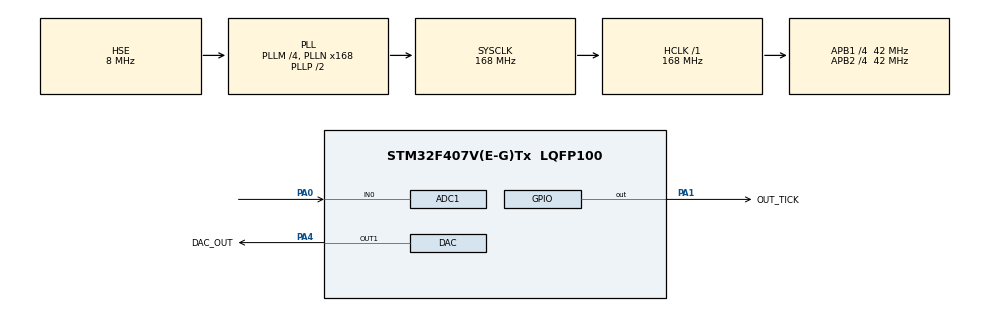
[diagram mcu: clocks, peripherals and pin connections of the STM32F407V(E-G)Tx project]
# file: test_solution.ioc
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ADC1.Channel-19\#ChannelRegularConversion=ADC_CHANNEL_0
ADC1.ClockPrescaler=ADC_CLOCK_SYNC_PCLK_DIV4
ADC1.ContinuousConvMode=DISABLE
ADC1.DMAContinuousRequests=ENABLE
ADC1.ExternalTrigConv=ADC_EXTERNALTRIGCONV_T2_TRGO
ADC1.NbrOfConversionFlag=1
ADC1.Rank-19\#ChannelRegularConversion=1
ADC1.SamplingTime-19\#ChannelRegularConversion=ADC_SAMPLETIME_3CYCLES
ADC1.ScanConvMode=DISABLE
ADC1.master=1
DAC.DAC_OutputBuffer=DAC_OUTPUTBUFFER_ENABLE
Dma.ADC1.0.Direction=DMA_PERIPH_TO_MEMORY
Dma.ADC1.0.FIFOMode=DMA_FIFOMODE_DISABLE
Dma.ADC1.0.Instance=DMA2_Stream0
Dma.ADC1.0.MemDataAlignment=DMA_MDATAALIGN_HALFWORD
Dma.ADC1.0.MemInc=DMA_MINC_ENABLE
Dma.ADC1.0.Mode=DMA_CIRCULAR
Dma.ADC1.0.PeriphDataAlignment=DMA_PDATAALIGN_HALFWORD
Dma.ADC1.0.PeriphInc=DMA_PINC_DISABLE
Dma.ADC1.0.Priority=DMA_PRIORITY_LOW
Dma.Request0=ADC1
Mcu.Family=STM32F4
Mcu.Name=STM32F407V(E-G)Tx
Mcu.Package=LQFP100
NVIC.DMA2_Stream0_IRQn=true\:0\:0\:false\:false\:true\:false\:true
NVIC.PriorityGroup=NVIC_PRIORITYGROUP_0
PA0-WKUP.Signal=ADCx_IN0
PA1.GPIO_Label=OUT_TICK
PA1.GPIO_PuPd=GPIO_PULLUP
PA1.Signal=GPIO_Output
PA4.GPIO_Label=DAC_OUT
PA4.Signal=COMP_DAC1_group
PC14-OSC32_IN.Mode=LSE-External-Oscillator
PC14-OSC32_IN.Signal=RCC_OSC32_IN
PC15-OSC32_OUT.Mode=LSE-External-Oscillator
PC15-OSC32_OUT.Signal=RCC_OSC32_OUT
PH0-OSC_IN.Mode=HSE-External-Oscillator
PH0-OSC_IN.Signal=RCC_OSC_IN
PH1-OSC_OUT.Mode=HSE-External-Oscillator
PH1-OSC_OUT.Signal=RCC_OSC_OUT
ProjectManager.HeapSize=0x200
ProjectManager.StackSize=0x400
ProjectManager.TargetToolchain=MDK-ARM V5.27
RCC.48MHZClocksFreq_Value=84000000
RCC.AHBFreq_Value=168000000
RCC.APB1CLKDivider=RCC_HCLK_DIV4
RCC.APB1Freq_Value=42000000
RCC.APB1TimFreq_Value=84000000
RCC.APB2CLKDivider=RCC_HCLK_DIV4
RCC.APB2Freq_Value=42000000
RCC.APB2TimFreq_Value=84000000
RCC.CortexFreq_Value=168000000
RCC.HCLKFreq_Value=168000000
RCC.HSE_VALUE=8000000
RCC.HSI_VALUE=16000000
RCC.PLLM=4
RCC.PLLN=168
RCC.PLLSourceVirtual=RCC_PLLSOURCE_HSE
RCC.SYSCLKFreq_VALUE=168000000
RCC.SYSCLKSource=RCC_SYSCLKSOURCE_PLLCLK
RCC.VCOOutputFreq_Value=336000000
SH.ADCx_IN0.0=ADC1_IN0,IN0
SH.COMP_DAC1_group.0=DAC_OUT1,DAC_OUT1
TIM2.AutoReloadPreload=TIM_AUTORELOAD_PRELOAD_ENABLE
TIM2.ClockDivision=TIM_CLOCKDIVISION_DIV1
TIM2.Period=200
TIM2.Prescaler=83
TIM2.TIM_MasterOutputTrigger=TIM_TRGO_UPDATE
VP_RTC_VS_RTC_Activate.Mode=RTC_Enabled
VP_TIM2_VS_ClockSourceINT.Mode=Internal
board=custom

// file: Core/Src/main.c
/* USER CODE BEGIN Header */
/**
  ******************************************************************************
  * @file           : main.c
  * @brief          : Тестовое задание
	* @authors        : Селютин Алексей
	* @date           : 19.11.2023
	* @todo           Что можно добавить: - калибровку ADC и измерение Vref. Это может повысить точность измерений.
	* @n Можно ввести два буфера для DMA и включить мультибуфер (актуально для высокой частоты дискредитации ADC)
	* @warning По причине отсутствия выхода SWO ST-LINK2 - вывод отладочной информации в терминал не тестировался.
	* @n Для включения вывода в терминал должно быть достаточно включить #define PRINTF_ENABLE
  ******************************************************************************
  *
  * <h2><center>&copy; Copyright (c) 2023 STMicroelectronics.
  * All rights reserved.</center></h2>
  *
  * This software component is licensed by ST under BSD 3-Clause license,
  * the "License"; You may not use this file except in compliance with the
  * License. You may obtain a copy of the License at:
  *                        opensource.org/licenses/BSD-3-Clause
  *
  ******************************************************************************
  */
/* USER CODE END Header */
#include "main.h"

/* USER CODE BEGIN Includes */
#include "stdio.h"

/* USER CODE END Includes */

/* USER CODE BEGIN PD */
//#define PRINTF_ENABLE /**< Разрешить отладку в терминале*/
/* USER CODE END PD */

DAC_HandleTypeDef hdac;

RTC_HandleTypeDef hrtc;

TIM_HandleTypeDef htim2;

void SystemClock_Config(void);
static void MX_GPIO_Init(void);
static void MX_DMA_Init(void);
static void MX_ADC1_Init(void);
static void MX_DAC_Init(void);
static void MX_RTC_Init(void);
static void MX_TIM2_Init(void);
/* USER CODE BEGIN PFP */

#ifdef PRINTF_ENABLE
#define ITM_Port8(n)    (*((volatile unsigned char *)(0xE0000000+4*n)))
#define ITM_Port16(n)   (*((volatile unsigned short*)(0xE0000000+4*n)))
#define ITM_Port32(n)   (*((volatile unsigned long *)(0xE0000000+4*n)))
#define DEMCR           (*((volatile unsigned long *)(0xE000EDFC)))
#define TRCENA          0x01000000

FILE __stdout;
FILE __stdin;

int fputc(int ch, FILE *f)
{
  if (DEMCR & TRCENA)
	{

		while (ITM_Port32(0) == 0);
    ITM_Port8(0) = ch;
	}
  return(ch);
}
#endif
/* USER CODE END PFP */

/* USER CODE BEGIN 0 */

/**
	*Размер буфера DMA
	*/
#define ADC_BUF_SIZE 125
uint16_t	ADC_data[ADC_BUF_SIZE]; /**< Буфер для данных из ADC. При частоте дискретизации 5кГц заполняется за 25 мс*/
uint32_t	result = 0;             /**< Сумма значний всех преобразований за 1 секунду*/
volatile uint8_t		f_ready = 0;  /**< Флаг готовности данных для вывода в отладочный терминал (раз в секунду) */
/* USER CODE END 0 */

int main(void)
{

  /* MCU Configuration--------------------------------------------------------*/

  /* Reset of all peripherals, Initializes the Flash interface and the Systick. */
  HAL_Init();

  /* Configure the system clock */
  SystemClock_Config();

  /* Initialize all configured peripherals */
  MX_GPIO_Init();
  MX_DMA_Init();
  MX_ADC1_Init();
  MX_DAC_Init();
  MX_RTC_Init();
  MX_TIM2_Init();
  /* USER CODE BEGIN 2 */
  LL_DMA_ConfigAddresses( DMA2, LL_DMA_STREAM_0, LL_ADC_DMA_GetRegAddr(ADC1, LL_ADC_DMA_REG_REGULAR_DATA), (uint32_t)ADC_data, LL_DMA_DIRECTION_PERIPH_TO_MEMORY);

  // DAC enable
	HAL_DAC_Start(&hdac, DAC_CHANNEL_1);
  HAL_DAC_SetValue(&hdac, DAC_CHANNEL_1, DAC_ALIGN_12B_R, 0);

  // configure DMA length
  LL_DMA_SetDataLength(DMA2, LL_DMA_STREAM_0, sizeof(ADC_data)/sizeof(ADC_data[0]));
  // enable DMA tranfer complete interrupt
  LL_DMA_EnableIT_TC(DMA2, LL_DMA_STREAM_0);
  // enable DMA stream
  LL_DMA_EnableStream(DMA2, LL_DMA_STREAM_0);
  // enable ADC
  LL_ADC_Enable(ADC1);

  // start conversion
	LL_ADC_REG_StartConversionExtTrig(ADC1, LL_ADC_REG_TRIG_EXT_RISING);
 // LL_ADC_REG_StartConversionSWStart(ADC1);
  /* USER CODE END 2 */

  /* Infinite loop */
  while (1)
  {

    /* USER CODE BEGIN 3 */
		if (f_ready==1)
		{
			f_ready = 0;

			result /= 5000;
			result *= 3300;
			result /= 0x0FFF;
#ifdef PRINTF_ENABLE
			printf("%d mV\r\n", result);
#endif
		}

  }
  /* USER CODE END 3 */
}

void SystemClock_Config(void)
{
  RCC_OscInitTypeDef RCC_OscInitStruct = {0};
  RCC_ClkInitTypeDef RCC_ClkInitStruct = {0};
  RCC_PeriphCLKInitTypeDef PeriphClkInitStruct = {0};

  /** Configure the main internal regulator output voltage
  */
  __HAL_RCC_PWR_CLK_ENABLE();
  __HAL_PWR_VOLTAGESCALING_CONFIG(PWR_REGULATOR_VOLTAGE_SCALE1);
  /** Initializes the RCC Oscillators according to the specified parameters
  * in the RCC_OscInitTypeDef structure.
  */
  RCC_OscInitStruct.OscillatorType = RCC_OSCILLATORTYPE_LSI|RCC_OSCILLATORTYPE_HSE;
  RCC_OscInitStruct.HSEState = RCC_HSE_ON;
  RCC_OscInitStruct.LSIState = RCC_LSI_ON;
  RCC_OscInitStruct.PLL.PLLState = RCC_PLL_ON;
  RCC_OscInitStruct.PLL.PLLSource = RCC_PLLSOURCE_HSE;
  RCC_OscInitStruct.PLL.PLLM = 4;
  RCC_OscInitStruct.PLL.PLLN = 168;
  RCC_OscInitStruct.PLL.PLLP = RCC_PLLP_DIV2;
  RCC_OscInitStruct.PLL.PLLQ = 4;
  if (HAL_RCC_OscConfig(&RCC_OscInitStruct) != HAL_OK)
  {
    Error_Handler();
  }
  /** Initializes the CPU, AHB and APB buses clocks
  */
  RCC_ClkInitStruct.ClockType = RCC_CLOCKTYPE_HCLK|RCC_CLOCKTYPE_SYSCLK
                              |RCC_CLOCKTYPE_PCLK1|RCC_CLOCKTYPE_PCLK2;
  RCC_ClkInitStruct.SYSCLKSource = RCC_SYSCLKSOURCE_PLLCLK;
  RCC_ClkInitStruct.AHBCLKDivider = RCC_SYSCLK_DIV1;
  RCC_ClkInitStruct.APB1CLKDivider = RCC_HCLK_DIV4;
  RCC_ClkInitStruct.APB2CLKDivider = RCC_HCLK_DIV4;

  if (HAL_RCC_ClockConfig(&RCC_ClkInitStruct, FLASH_LATENCY_5) != HAL_OK)
  {
    Error_Handler();
  }
  PeriphClkInitStruct.PeriphClockSelection = RCC_PERIPHCLK_RTC;
  PeriphClkInitStruct.RTCClockSelection = RCC_RTCCLKSOURCE_LSI;
  if (HAL_RCCEx_PeriphCLKConfig(&PeriphClkInitStruct) != HAL_OK)
  {
    Error_Handler();
  }
}

static void MX_ADC1_Init(void)
{

  LL_ADC_InitTypeDef ADC_InitStruct = {0};
  LL_ADC_REG_InitTypeDef ADC_REG_InitStruct = {0};
  LL_ADC_CommonInitTypeDef ADC_CommonInitStruct = {0};

  LL_GPIO_InitTypeDef GPIO_InitStruct = {0};

  /* Peripheral clock enable */
  LL_APB2_GRP1_EnableClock(LL_APB2_GRP1_PERIPH_ADC1);

  LL_AHB1_GRP1_EnableClock(LL_AHB1_GRP1_PERIPH_GPIOA);
  /**ADC1 GPIO Configuration
  PA0-WKUP   ------> ADC1_IN0
  */
  GPIO_InitStruct.Pin = LL_GPIO_PIN_0;
  GPIO_InitStruct.Mode = LL_GPIO_MODE_ANALOG;
  GPIO_InitStruct.Pull = LL_GPIO_PULL_NO;
  LL_GPIO_Init(GPIOA, &GPIO_InitStruct);

  /* ADC1 DMA Init */

  /* ADC1 Init */
  LL_DMA_SetChannelSelection(DMA2, LL_DMA_STREAM_0, LL_DMA_CHANNEL_0);

  LL_DMA_SetDataTransferDirection(DMA2, LL_DMA_STREAM_0, LL_DMA_DIRECTION_PERIPH_TO_MEMORY);

  LL_DMA_SetStreamPriorityLevel(DMA2, LL_DMA_STREAM_0, LL_DMA_PRIORITY_LOW);

  LL_DMA_SetMode(DMA2, LL_DMA_STREAM_0, LL_DMA_MODE_CIRCULAR);

  LL_DMA_SetPeriphIncMode(DMA2, LL_DMA_STREAM_0, LL_DMA_PERIPH_NOINCREMENT);

  LL_DMA_SetMemoryIncMode(DMA2, LL_DMA_STREAM_0, LL_DMA_MEMORY_INCREMENT);

  LL_DMA_SetPeriphSize(DMA2, LL_DMA_STREAM_0, LL_DMA_PDATAALIGN_HALFWORD);

  LL_DMA_SetMemorySize(DMA2, LL_DMA_STREAM_0, LL_DMA_MDATAALIGN_HALFWORD);

  LL_DMA_DisableFifoMode(DMA2, LL_DMA_STREAM_0);

  /** Common config
  */
  ADC_InitStruct.Resolution = LL_ADC_RESOLUTION_12B;
  ADC_InitStruct.DataAlignment = LL_ADC_DATA_ALIGN_RIGHT;
  ADC_InitStruct.SequencersScanMode = LL_ADC_SEQ_SCAN_DISABLE;
  LL_ADC_Init(ADC1, &ADC_InitStruct);
  ADC_REG_InitStruct.TriggerSource = LL_ADC_REG_TRIG_EXT_TIM2_TRGO;
  ADC_REG_InitStruct.SequencerLength = LL_ADC_REG_SEQ_SCAN_DISABLE;
  ADC_REG_InitStruct.SequencerDiscont = LL_ADC_REG_SEQ_DISCONT_DISABLE;
  ADC_REG_InitStruct.ContinuousMode = LL_ADC_REG_CONV_SINGLE;
  ADC_REG_InitStruct.DMATransfer = LL_ADC_REG_DMA_TRANSFER_UNLIMITED;
  LL_ADC_REG_Init(ADC1, &ADC_REG_InitStruct);
  LL_ADC_REG_SetFlagEndOfConversion(ADC1, LL_ADC_REG_FLAG_EOC_UNITARY_CONV);
  ADC_CommonInitStruct.CommonClock = LL_ADC_CLOCK_SYNC_PCLK_DIV4;
  ADC_CommonInitStruct.Multimode = LL_ADC_MULTI_INDEPENDENT;
  LL_ADC_CommonInit(__LL_ADC_COMMON_INSTANCE(ADC1), &ADC_CommonInitStruct);
  LL_ADC_REG_StartConversionExtTrig(ADC1, LL_ADC_REG_TRIG_EXT_RISING);
  /** Configure Regular Channel
  */
  LL_ADC_REG_SetSequencerRanks(ADC1, LL_ADC_REG_RANK_1, LL_ADC_CHANNEL_0);
  LL_ADC_SetChannelSamplingTime(ADC1, LL_ADC_CHANNEL_0, LL_ADC_SAMPLINGTIME_3CYCLES);

}

static void MX_DAC_Init(void)
{

  DAC_ChannelConfTypeDef sConfig = {0};

  /** DAC Initialization
  */
  hdac.Instance = DAC;
  if (HAL_DAC_Init(&hdac) != HAL_OK)
  {
    Error_Handler();
  }
  /** DAC channel OUT1 config
  */
  sConfig.DAC_Trigger = DAC_TRIGGER_NONE;
  sConfig.DAC_OutputBuffer = DAC_OUTPUTBUFFER_ENABLE;
  if (HAL_DAC_ConfigChannel(&hdac, &sConfig, DAC_CHANNEL_1) != HAL_OK)
  {
    Error_Handler();
  }

}

static void MX_RTC_Init(void)
{

  /** Initialize RTC Only
  */
  hrtc.Instance = RTC;
  hrtc.Init.HourFormat = RTC_HOURFORMAT_24;
  hrtc.Init.AsynchPrediv = 127;
  hrtc.Init.SynchPrediv = 255;
  hrtc.Init.OutPut = RTC_OUTPUT_DISABLE;
  hrtc.Init.OutPutPolarity = RTC_OUTPUT_POLARITY_HIGH;
  hrtc.Init.OutPutType = RTC_OUTPUT_TYPE_OPENDRAIN;
  if (HAL_RTC_Init(&hrtc) != HAL_OK)
  {
    Error_Handler();
  }

}

static void MX_TIM2_Init(void)
{

  TIM_ClockConfigTypeDef sClockSourceConfig = {0};
  TIM_MasterConfigTypeDef sMasterConfig = {0};

  htim2.Instance = TIM2;
  htim2.Init.Prescaler = 83;
  htim2.Init.CounterMode = TIM_COUNTERMODE_UP;
  htim2.Init.Period = 200;
  htim2.Init.ClockDivision = TIM_CLOCKDIVISION_DIV1;
  htim2.Init.AutoReloadPreload = TIM_AUTORELOAD_PRELOAD_ENABLE;
  if (HAL_TIM_Base_Init(&htim2) != HAL_OK)
  {
    Error_Handler();
  }
  sClockSourceConfig.ClockSource = TIM_CLOCKSOURCE_INTERNAL;
  if (HAL_TIM_ConfigClockSource(&htim2, &sClockSourceConfig) != HAL_OK)
  {
    Error_Handler();
  }
  sMasterConfig.MasterOutputTrigger = TIM_TRGO_UPDATE;
  sMasterConfig.MasterSlaveMode = TIM_MASTERSLAVEMODE_DISABLE;
  if (HAL_TIMEx_MasterConfigSynchronization(&htim2, &sMasterConfig) != HAL_OK)
  {
    Error_Handler();
  }
  /* USER CODE BEGIN TIM2_Init 2 */
	HAL_TIM_Base_Start(&htim2);
  /* USER CODE END TIM2_Init 2 */

}

static void MX_DMA_Init(void)
{

  /* DMA controller clock enable */
  __HAL_RCC_DMA2_CLK_ENABLE();

  /* DMA interrupt init */
  /* DMA2_Stream0_IRQn interrupt configuration */
  NVIC_SetPriority(DMA2_Stream0_IRQn, NVIC_EncodePriority(NVIC_GetPriorityGrouping(),0, 0));
  NVIC_EnableIRQ(DMA2_Stream0_IRQn);

}

static void MX_GPIO_Init(void)
{
  GPIO_InitTypeDef GPIO_InitStruct = {0};

  /* GPIO Ports Clock Enable */
  __HAL_RCC_GPIOC_CLK_ENABLE();
  __HAL_RCC_GPIOH_CLK_ENABLE();
  __HAL_RCC_GPIOA_CLK_ENABLE();

  /*Configure GPIO pin Output Level */
  HAL_GPIO_WritePin(OUT_TICK_GPIO_Port, OUT_TICK_Pin, GPIO_PIN_RESET);

  /*Configure GPIO pin : OUT_TICK_Pin */
  GPIO_InitStruct.Pin = OUT_TICK_Pin;
  GPIO_InitStruct.Mode = GPIO_MODE_OUTPUT_PP;
  GPIO_InitStruct.Pull = GPIO_PULLUP;
  GPIO_InitStruct.Speed = GPIO_SPEED_FREQ_LOW;
  HAL_GPIO_Init(OUT_TICK_GPIO_Port, &GPIO_InitStruct);

}

/* USER CODE BEGIN 4 */
/**
	* Обработка буфера данных от ADC. Вызывается из прерывания DMA раз 25мс.
  * Усредняет 125 значений из ADC и выставляет в DAC
	*/
void ADC_DMA_TransferComplete_Callback()
{
	uint32_t summ = 0;
	static uint32_t big_summ = 0;
	static uint8_t count = 0;
	for (uint16_t i=0; i<sizeof(ADC_data)/sizeof(ADC_data[0]) ;i++)
		summ+=ADC_data[i];
	big_summ+=summ;
	summ/=sizeof(ADC_data)/sizeof(ADC_data[0]);
  HAL_DAC_SetValue(&hdac, DAC_CHANNEL_1, DAC_ALIGN_12B_R, summ);

	if (++count>=40)
	{
		HAL_GPIO_TogglePin(OUT_TICK_GPIO_Port, OUT_TICK_Pin);
		f_ready = 1;
		result = big_summ;
		big_summ = 0;
		count = 0;
	}
}
/* USER CODE END 4 */

void Error_Handler(void)
{
  __disable_irq();
  while (1)
  {
  }
}

/************************ (C) COPYRIGHT STMicroelectronics *****END OF FILE****/
